AUTOSAR XML (schema 4-0-3)
package /ComponentTypes
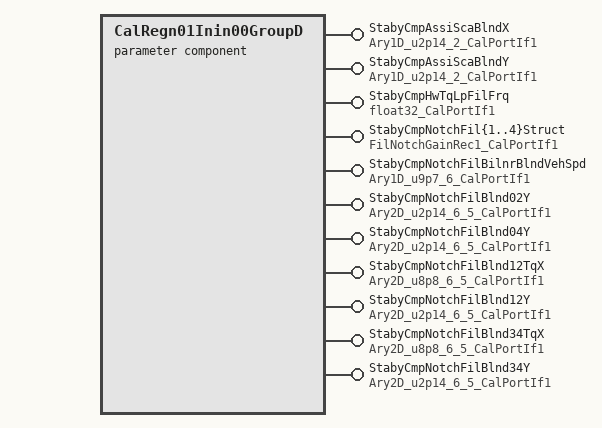
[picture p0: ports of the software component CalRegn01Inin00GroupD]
  parameter sw component type CalRegn01Inin00GroupD
    14 x provide port:
      StabyCmpAssiScaBlndX: parameter-provide-com-spec{init-value=[16384, 32768], parameter=Ary1D}, provided-interface=Ary1D_u2p14_2_CalPortIf1
      StabyCmpAssiScaBlndY: parameter-provide-com-spec{init-value=[0, 0], parameter=Ary1D}, provided-interface=Ary1D_u2p14_2_CalPortIf1
      StabyCmpHwTqLpFilFrq: parameter-provide-com-spec{init-value=30, parameter=Val}, provided-interface=float32_CalPortIf1
      StabyCmpNotchFil{1..4}Struct: parameter-provide-com-spec=Rec, provided-interface=FilNotchGainRec1_CalPortIf1
      StabyCmpNotchFilBilnrBlndVehSpd: parameter-provide-com-spec{init-value=[0, 1280, 3840, 5760, 7680, 10240], parameter=Ary1D}, provided-interface=Ary1D_u9p7_6_CalPortIf1
      StabyCmpNotchFilBlnd02Y: parameter-provide-com-spec{init-value=6 x 5 x 16384, parameter=Ary2D}, provided-interface=Ary2D_u2p14_6_5_CalPortIf1
      StabyCmpNotchFilBlnd04Y: parameter-provide-com-spec{init-value=6 x 5 x 16384, parameter=Ary2D}, provided-interface=Ary2D_u2p14_6_5_CalPortIf1
      StabyCmpNotchFilBlnd12TqX: parameter-provide-com-spec{init-value=[5 x 0, 5 x 512, 5 x 768, 5 x 1024, 5 x 1536, 5 x 2048], parameter=Ary2D}, provided-interface=Ary2D_u8p8_6_5_CalPortIf1
      StabyCmpNotchFilBlnd12Y: parameter-provide-com-spec{init-value=6 x 5 x 0, parameter=Ary2D}, provided-interface=Ary2D_u2p14_6_5_CalPortIf1
      StabyCmpNotchFilBlnd34TqX: parameter-provide-com-spec{init-value=[5 x 0, 5 x 512, 5 x 768, 5 x 1024, 5 x 1536, 5 x 2048], parameter=Ary2D}, provided-interface=Ary2D_u8p8_6_5_CalPortIf1
      StabyCmpNotchFilBlnd34Y: parameter-provide-com-spec{init-value=6 x 5 x 0, parameter=Ary2D}, provided-interface=Ary2D_u2p14_6_5_CalPortIf1
